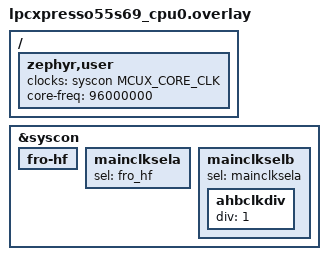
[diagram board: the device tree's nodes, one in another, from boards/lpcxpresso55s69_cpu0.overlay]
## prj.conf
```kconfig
CONFIG_ZTEST=y
CONFIG_ZTEST_NEW_API=y
CONFIG_NXP_DTS_CLOCKING=y
```

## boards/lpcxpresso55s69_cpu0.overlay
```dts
/*
 * Copyright 2023 NXP
 *
 * SPDX-License-Identifier: Apache-2.0
 *
 */

#include <zephyr/dt-bindings/clock/mcux_lpc_syscon_clock.h>

/ {
	zephyr,user {
		clocks = <&syscon MCUX_CORE_CLK>;
		core-freq = <96000000>;
	};
};

/* Setup core clock for 96MHz operation */
&syscon {
	/* Enable FRO HF */
	fro-hf {
		status = "okay";
	};

	/* Route FROHF to main clock */
	mainclksela {
		status = "okay";
		sel = <&fro_hf>;
	};

	mainclkselb {
		status = "okay";
		sel = <&mainclksela>;
		/* AHB clk div sets main system clock, which will be 96MHz */
		ahbclkdiv {
			status = "okay";
			div = <1>;
		};
	};
};
```

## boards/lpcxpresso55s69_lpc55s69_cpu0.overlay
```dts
/*
 * Copyright 2023 NXP
 *
 * SPDX-License-Identifier: Apache-2.0
 *
 */

/ {
	zephyr,user {
		clocks = <&syscon MCUX_SYSTEM_CLK>;
		core-freq = <96000000>;
	};
};

&cpus {
	clock-setpoints {
		run_setpoint: run-setpoint {
			compatible = "nxp,lpc55xxx-setpoint";
			#setpoint-cells = <0>;
			/* Enable FRO12M and FROHF clock sources */
			fro-12m-enable;
			fro-hf-enable;
			/* Source main clock from fro-hf */
			mainclksela = <MAINCLKSELA_FRO_HF>;
			mainclkselb = <MAINCLKSELB_MAINCLKSELA>;
			/* Source UART clock from FRO12M */
			fcclksel0 = <FCCLKSEL0_FRO_12M>;
			/* AHB clock divided by 1, final clock output will be 96MHz */
			ahbclkdiv = <1>;
		};
	};
};

&syscon {
	setpoints = <&run_setpoint>;
	setpoint-names = "run";
};
```

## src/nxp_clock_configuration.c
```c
/*
 * Copyright (c) 2019, Nordic Semiconductor ASA
 *
 * SPDX-License-Identifier: Apache-2.0
 */
#include <zephyr/ztest.h>
#include <zephyr/drivers/clock_control.h>
#include <zephyr/logging/log.h>
LOG_MODULE_REGISTER(test);

/* Variable defined at SOC level for system clock frequency */
const struct device *clock_dev = DEVICE_DT_GET(DT_CLOCKS_CTLR(DT_PATH(zephyr_user)));
const clock_control_subsys_t subsys =
	(clock_control_subsys_t)DT_CLOCKS_CELL(DT_PATH(zephyr_user), name);

ZTEST(nxp_clock_config, validate_freq) {
	int ret;
	uint32_t rate;

	ret = clock_control_get_rate(clock_dev, subsys, &rate);
	zassert_equal(ret, 0, "Could not get clock subsys rate");
	/* Validate that the system clock frequency matches what we expect */
	zassert_equal(rate, DT_PROP(DT_PATH(zephyr_user), core_freq));
	TC_PRINT("System Core clock was %d\n", rate);
};

ZTEST_SUITE(nxp_clock_config, NULL, NULL, NULL, NULL, NULL);
```
